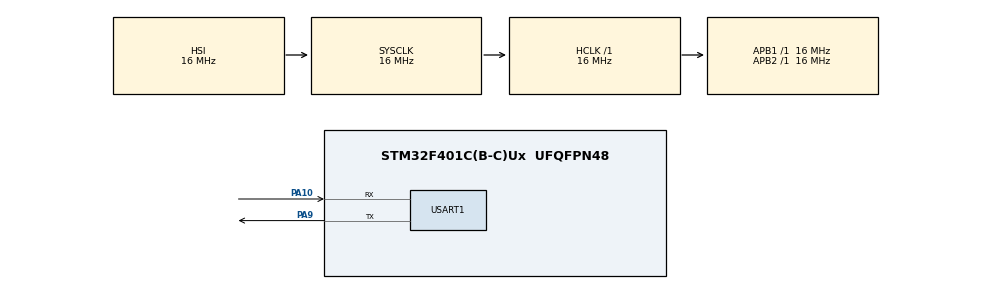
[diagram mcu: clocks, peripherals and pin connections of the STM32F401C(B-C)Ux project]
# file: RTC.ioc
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Mcu.Family=STM32F4
Mcu.Name=STM32F401C(B-C)Ux
Mcu.Package=UFQFPN48
NVIC.PriorityGroup=NVIC_PRIORITYGROUP_4
NVIC.RTC_Alarm_IRQn=true\:0\:0\:false\:false\:true\:true\:true\:true
PA10.Mode=Asynchronous
PA10.Signal=USART1_RX
PA9.Mode=Asynchronous
PA9.Signal=USART1_TX
PC14-OSC32_IN.Mode=LSE-External-Oscillator
PC14-OSC32_IN.Signal=RCC_OSC32_IN
PC15-OSC32_OUT.Mode=LSE-External-Oscillator
PC15-OSC32_OUT.Signal=RCC_OSC32_OUT
PH0\ -\ OSC_IN.Mode=HSE-External-Oscillator
PH0\ -\ OSC_IN.Signal=RCC_OSC_IN
PH1\ -\ OSC_OUT.Mode=HSE-External-Oscillator
PH1\ -\ OSC_OUT.Signal=RCC_OSC_OUT
ProjectManager.HeapSize=0x200
ProjectManager.StackSize=0x400
ProjectManager.TargetToolchain=STM32CubeIDE
RCC.AHBFreq_Value=16000000
RCC.APB1Freq_Value=16000000
RCC.APB2Freq_Value=16000000
RCC.CortexFreq_Value=16000000
RCC.HSE_VALUE=25000000
RCC.HSI_VALUE=16000000
RCC.SYSCLKFreq_VALUE=16000000
RCC.VCOOutputFreq_Value=192000000
RTC.Alarm=RTC_ALARM_A
RTC.HourFormat=RTC_HOURFORMAT_12
USART1.VirtualMode=VM_ASYNC
VP_RTC_VS_RTC_Activate.Mode=RTC_Enabled
VP_RTC_VS_RTC_Alarm_A_Intern.Mode=Alarm A
VP_RTC_VS_RTC_Calendar.Mode=RTC_Calendar
board=custom

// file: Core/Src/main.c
/* USER CODE BEGIN Header */
/**
  ******************************************************************************
  * @file           : main.c
  * @brief          : Main program body
  ******************************************************************************
  * @attention
  *
  * Copyright (c) 2025 STMicroelectronics.
  * All rights reserved.
  *
  * This software is licensed under terms that can be found in the LICENSE file
  * in the root directory of this software component.
  * If no LICENSE file comes with this software, it is provided AS-IS.
  *
  ******************************************************************************
  */
/* USER CODE END Header */
#include "main.h"

RTC_HandleTypeDef hrtc;

UART_HandleTypeDef huart1;

void Send_RTC_Time(void) {
    RTC_TimeTypeDef sTime;
    RTC_DateTypeDef sDate;
    char buffer[50];

    // Get the RTC current time and date
    HAL_RTC_GetTime(&hrtc, &sTime, RTC_FORMAT_BIN);
    HAL_RTC_GetDate(&hrtc, &sDate, RTC_FORMAT_BIN); // Necessary to unlock RTC shadow registers

    // Format the string
    snprintf(buffer, sizeof(buffer), "Time: %02d:%02d:%02d Date: %02d-%02d-20%02d\r\n",
             sTime.Hours, sTime.Minutes, sTime.Seconds,
             sDate.Date, sDate.Month, sDate.Year);

    // Send it over UART
    HAL_UART_Transmit(&huart1, (uint8_t *)buffer, strlen(buffer), HAL_MAX_DELAY);
}

void SystemClock_Config(void);
static void MX_GPIO_Init(void);
static void MX_RTC_Init(void);
static void MX_USART1_UART_Init(void);

int main(void)
{

  /* MCU Configuration--------------------------------------------------------*/

  /* Reset of all peripherals, Initializes the Flash interface and the Systick. */
  HAL_Init();

  /* Configure the system clock */
  SystemClock_Config();

  /* Initialize all configured peripherals */
  MX_GPIO_Init();
  MX_RTC_Init();
  MX_USART1_UART_Init();

  /* Infinite loop */
  while (1)
  {
	  Send_RTC_Time(); // Send RTC time over UART
	  HAL_Delay(1000); // Wait 1 second
  }
}

void SystemClock_Config(void)
{
  RCC_OscInitTypeDef RCC_OscInitStruct = {0};
  RCC_ClkInitTypeDef RCC_ClkInitStruct = {0};

  /** Configure the main internal regulator output voltage
  */
  __HAL_RCC_PWR_CLK_ENABLE();
  __HAL_PWR_VOLTAGESCALING_CONFIG(PWR_REGULATOR_VOLTAGE_SCALE2);

  /** Initializes the RCC Oscillators according to the specified parameters
  * in the RCC_OscInitTypeDef structure.
  */
  RCC_OscInitStruct.OscillatorType = RCC_OSCILLATORTYPE_HSI|RCC_OSCILLATORTYPE_LSI;
  RCC_OscInitStruct.HSIState = RCC_HSI_ON;
  RCC_OscInitStruct.HSICalibrationValue = RCC_HSICALIBRATION_DEFAULT;
  RCC_OscInitStruct.LSIState = RCC_LSI_ON;
  RCC_OscInitStruct.PLL.PLLState = RCC_PLL_NONE;
  if (HAL_RCC_OscConfig(&RCC_OscInitStruct) != HAL_OK)
  {
    Error_Handler();
  }

  /** Initializes the CPU, AHB and APB buses clocks
  */
  RCC_ClkInitStruct.ClockType = RCC_CLOCKTYPE_HCLK|RCC_CLOCKTYPE_SYSCLK
                              |RCC_CLOCKTYPE_PCLK1|RCC_CLOCKTYPE_PCLK2;
  RCC_ClkInitStruct.SYSCLKSource = RCC_SYSCLKSOURCE_HSI;
  RCC_ClkInitStruct.AHBCLKDivider = RCC_SYSCLK_DIV1;
  RCC_ClkInitStruct.APB1CLKDivider = RCC_HCLK_DIV1;
  RCC_ClkInitStruct.APB2CLKDivider = RCC_HCLK_DIV1;

  if (HAL_RCC_ClockConfig(&RCC_ClkInitStruct, FLASH_LATENCY_0) != HAL_OK)
  {
    Error_Handler();
  }
}

static void MX_RTC_Init(void)
{

  RTC_TimeTypeDef sTime = {0};
  RTC_DateTypeDef sDate = {0};
  RTC_AlarmTypeDef sAlarm = {0};

  /** Initialize RTC Only
  */
  hrtc.Instance = RTC;
  hrtc.Init.HourFormat = RTC_HOURFORMAT_12;
  hrtc.Init.AsynchPrediv = 127;
  hrtc.Init.SynchPrediv = 255;
  hrtc.Init.OutPut = RTC_OUTPUT_DISABLE;
  hrtc.Init.OutPutPolarity = RTC_OUTPUT_POLARITY_HIGH;
  hrtc.Init.OutPutType = RTC_OUTPUT_TYPE_OPENDRAIN;
  if (HAL_RTC_Init(&hrtc) != HAL_OK)
  {
    Error_Handler();
  }

  /** Initialize RTC and set the Time and Date
  */
  sTime.Hours = 0x1;
  sTime.Minutes = 0x0;
  sTime.Seconds = 0x0;
  sTime.TimeFormat = RTC_HOURFORMAT12_AM;
  sTime.DayLightSaving = RTC_DAYLIGHTSAVING_NONE;
  sTime.StoreOperation = RTC_STOREOPERATION_RESET;
  if (HAL_RTC_SetTime(&hrtc, &sTime, RTC_FORMAT_BCD) != HAL_OK)
  {
    Error_Handler();
  }
  sDate.WeekDay = RTC_WEEKDAY_MONDAY;
  sDate.Month = RTC_MONTH_JANUARY;
  sDate.Date = 0x1;
  sDate.Year = 0x0;

  if (HAL_RTC_SetDate(&hrtc, &sDate, RTC_FORMAT_BCD) != HAL_OK)
  {
    Error_Handler();
  }

  /** Enable the Alarm A
  */
  sAlarm.AlarmTime.Hours = 0x1;
  sAlarm.AlarmTime.Minutes = 0x0;
  sAlarm.AlarmTime.Seconds = 0x0;
  sAlarm.AlarmTime.SubSeconds = 0x0;
  sAlarm.AlarmTime.TimeFormat = RTC_HOURFORMAT12_AM;
  sAlarm.AlarmTime.DayLightSaving = RTC_DAYLIGHTSAVING_NONE;
  sAlarm.AlarmTime.StoreOperation = RTC_STOREOPERATION_RESET;
  sAlarm.AlarmMask = RTC_ALARMMASK_NONE;
  sAlarm.AlarmSubSecondMask = RTC_ALARMSUBSECONDMASK_ALL;
  sAlarm.AlarmDateWeekDaySel = RTC_ALARMDATEWEEKDAYSEL_DATE;
  sAlarm.AlarmDateWeekDay = 0x1;
  sAlarm.Alarm = RTC_ALARM_A;
  if (HAL_RTC_SetAlarm_IT(&hrtc, &sAlarm, RTC_FORMAT_BCD) != HAL_OK)
  {
    Error_Handler();
  }

}

static void MX_USART1_UART_Init(void)
{

  huart1.Instance = USART1;
  huart1.Init.BaudRate = 115200;
  huart1.Init.WordLength = UART_WORDLENGTH_8B;
  huart1.Init.StopBits = UART_STOPBITS_1;
  huart1.Init.Parity = UART_PARITY_NONE;
  huart1.Init.Mode = UART_MODE_TX_RX;
  huart1.Init.HwFlowCtl = UART_HWCONTROL_NONE;
  huart1.Init.OverSampling = UART_OVERSAMPLING_16;
  if (HAL_UART_Init(&huart1) != HAL_OK)
  {
    Error_Handler();
  }

}

static void MX_GPIO_Init(void)
{

  /* GPIO Ports Clock Enable */
  __HAL_RCC_GPIOC_CLK_ENABLE();
  __HAL_RCC_GPIOH_CLK_ENABLE();
  __HAL_RCC_GPIOA_CLK_ENABLE();

}

/* USER CODE BEGIN 4 */
void HAL_RTC_AlarmAEventCallback(RTC_HandleTypeDef *hrtc) {
    char msg[] = "ALARM TRIGGERED!\r\n";
    HAL_UART_Transmit(&huart1, (uint8_t *)msg, strlen(msg), HAL_MAX_DELAY);
}

/* USER CODE END 4 */

void Error_Handler(void)
{
  __disable_irq();
  while (1)
  {
  }
}
